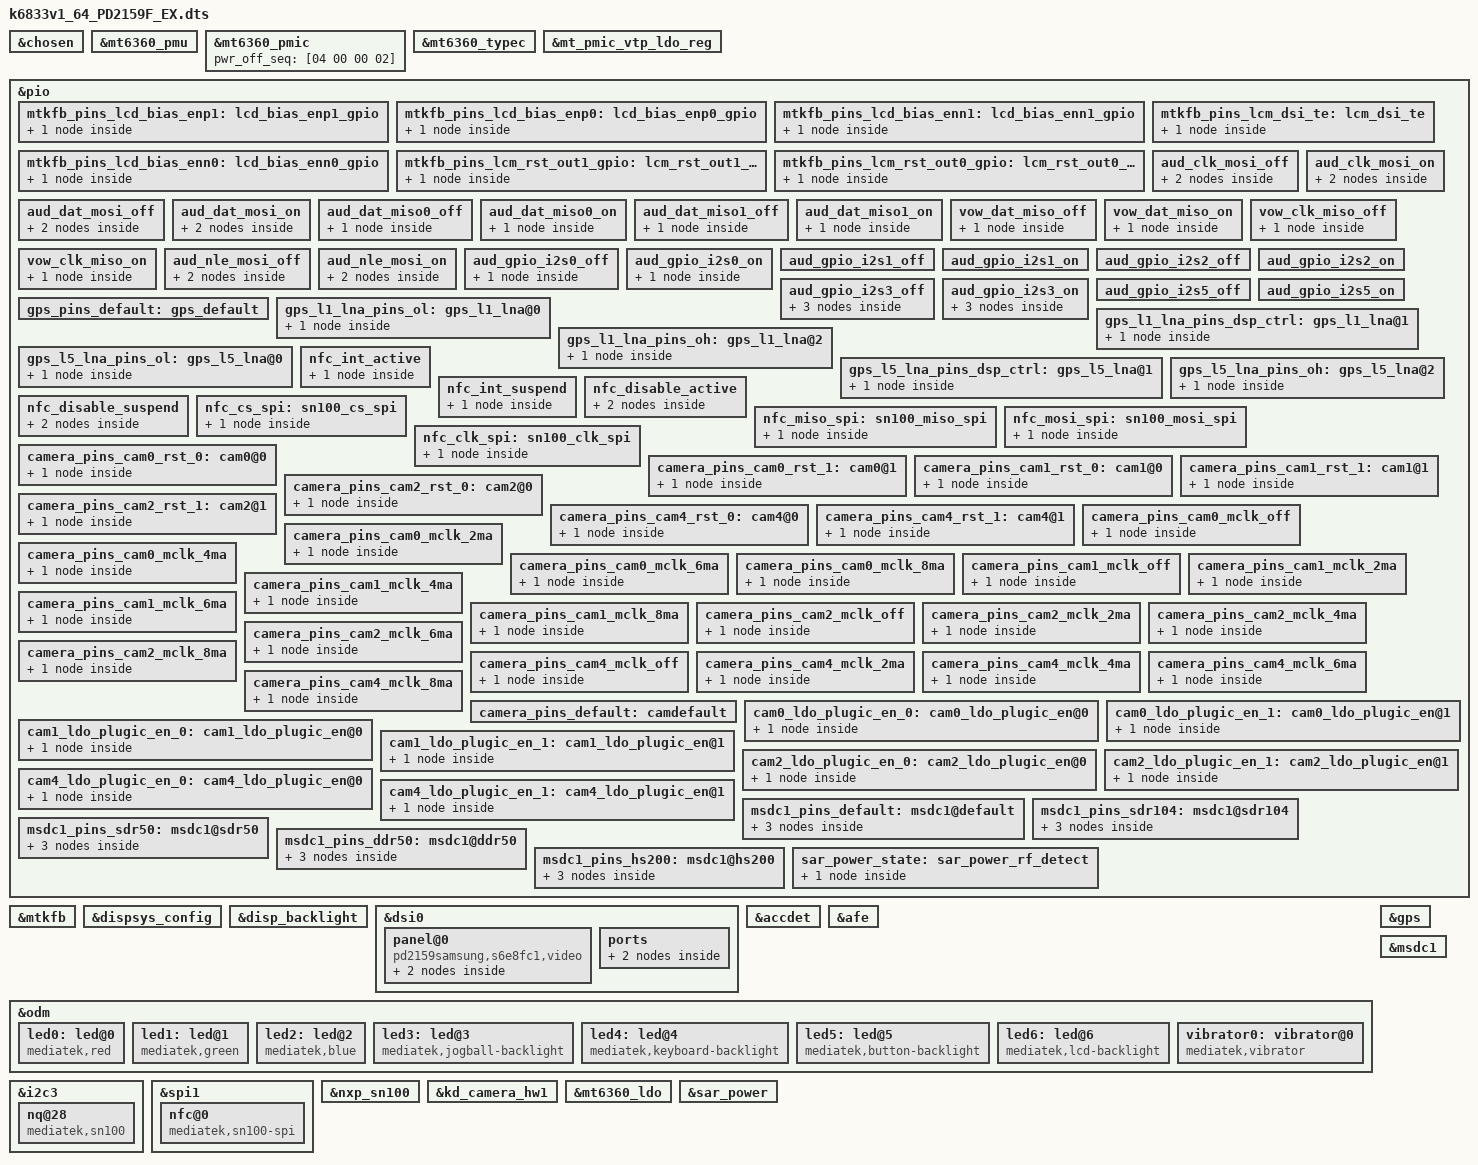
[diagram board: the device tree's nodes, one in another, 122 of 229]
/*
 * Mediatek's mt6833 SoC device tree source
 *
 * Copyright (C) 2016 MediaTek Inc.
 *
 * This program is free software; you can redistribute it and/or modify
 * it under the terms of the GNU General Public License version 2 as
 * published by the Free Software Foundation.
 *
 * This program is distributed in the hope that it will be useful,
 * but WITHOUT ANY WARRANTY; without even the implied warranty of
 * MERCHANTABILITY or FITNESS FOR A PARTICULAR PURPOSE.
 * See http://www.gnu.org/licenses/gpl-2.0.html for more details.
 */
/dts-v1/;
/plugin/;
#include <generated/autoconf.h>
#include <dt-bindings/interrupt-controller/irq.h>
#include <dt-bindings/interrupt-controller/arm-gic.h>
#ifndef CONFIG_FPGA_EARLY_PORTING
#include <dt-bindings/pinctrl/mt6833-pinfunc.h>
#endif

/* chosen */
&chosen {
	atag,videolfb-fb_base_l = <0x7e605000>;
	atag,videolfb-fb_base_h = <0x0>;
	atag,videolfb-islcmfound = <1>;
	atag,videolfb-islcm_inited = <0>;
	atag,videolfb-fps= <6000>;
	atag,videolfb-vramSize= <0x1be0000>;
	atag,videolfb-lcmname=
		"nt35595_fhd_dsi_cmd_truly_nt50358_drv";
	atag,videolfb-project-name= "pd2159";
	atag,vivo-dsi-panel-type = "oled";
	atag,exception-event-support;
	default-backlight-level = <573>;
//	bias-ic-use-i2c = <6>;
//	bl-ic-use-i2c = <6>;
};

&mt6360_pmu {
	mt6360,intr_gpio_num = <10>; /* direct defined GPIO num */
	mt6360,intr_gpio = <&pio 10 0x0>;
};

&mt6360_pmic {
	pwr_off_seq = [04 00 00 02];
};

&mt6360_typec {
	mt6360pd,intr_gpio_num = <9>; /* direct defined GPIO num */
	mt6360pd,intr_gpio = <&pio 9 0x0>;
};

/* add by sensor team for Psensor LED LDO2*/
&mt_pmic_vtp_ldo_reg {
	regulator-min-microvolt = <3000000>;
	regulator-max-microvolt = <3000000>;
	regulator-always-on;
};

#ifndef CONFIG_FPGA_EARLY_PORTING
&pio {
	mtkfb_pins_lcd_bias_enp1: lcd_bias_enp1_gpio {
		pins_cmd_dat {
			pinmux = <PINMUX_GPIO137__FUNC_GPIO137>;
			slew-rate = <1>;
			output-high;
		};
	};

	mtkfb_pins_lcd_bias_enp0: lcd_bias_enp0_gpio {
		pins_cmd_dat {
			pinmux = <PINMUX_GPIO137__FUNC_GPIO137>;
			slew-rate = <1>;
			output-low;
		};
	};

	mtkfb_pins_lcd_bias_enn1: lcd_bias_enn1_gpio {
		pins_cmd_dat {
			pinmux = <PINMUX_GPIO138__FUNC_GPIO138>;
			slew-rate = <1>;
			output-high;
		};
	};

	mtkfb_pins_lcd_bias_enn0: lcd_bias_enn0_gpio {
		pins_cmd_dat {
			pinmux = <PINMUX_GPIO138__FUNC_GPIO138>;
			slew-rate = <1>;
			output-low;
		};
	};

	mtkfb_pins_lcm_rst_out1_gpio: lcm_rst_out1_gpio {
		pins_cmd_dat {
			pinmux = <PINMUX_GPIO86__FUNC_GPIO86>;
			slew-rate = <1>;
			output-high;
		};
	};

	mtkfb_pins_lcm_rst_out0_gpio: lcm_rst_out0_gpio {
		pins_cmd_dat {
			pinmux = <PINMUX_GPIO86__FUNC_GPIO86>;
			slew-rate = <1>;
			output-low;
		};
	};
	mtkfb_pins_lcm_dsi_te: lcm_dsi_te {
		pins_cmd_dat {
			pinmux = <PINMUX_GPIO84__FUNC_DSI_TE>;
		};
	};
};

&mtkfb {
	pinctrl-names = "lcd_bias_enp1_gpio", "lcd_bias_enp0_gpio",
		"lcd_bias_enn1_gpio", "lcd_bias_enn0_gpio",
		"lcm_rst_out1_gpio", "lcm_rst_out0_gpio",
		"mode_te_te";
	pinctrl-0 = <&mtkfb_pins_lcd_bias_enp1>;
	pinctrl-1 = <&mtkfb_pins_lcd_bias_enp0>;
	pinctrl-2 = <&mtkfb_pins_lcd_bias_enn1>;
	pinctrl-3 = <&mtkfb_pins_lcd_bias_enn0>;
	pinctrl-4 = <&mtkfb_pins_lcm_rst_out1_gpio>;
	pinctrl-5 = <&mtkfb_pins_lcm_rst_out0_gpio>;
	pinctrl-6 = <&mtkfb_pins_lcm_dsi_te>;
	status = "okay";
};
&dispsys_config {
	pinctrl-names =
		"lcm_rst_out1_gpio", "lcm_rst_out0_gpio",
		"mode_te_te";
	pinctrl-0 = <&mtkfb_pins_lcm_rst_out1_gpio>;
	pinctrl-1 = <&mtkfb_pins_lcm_rst_out0_gpio>;
	pinctrl-2 = <&mtkfb_pins_lcm_dsi_te>;
	status = "okay";
		helper-name = "MTK_DRM_OPT_STAGE",
			"MTK_DRM_OPT_USE_CMDQ",
			"MTK_DRM_OPT_USE_M4U",
			"MTK_DRM_OPT_SODI_SUPPORT",
			"MTK_DRM_OPT_IDLE_MGR",
			"MTK_DRM_OPT_IDLEMGR_SWTCH_DECOUPLE",
			"MTK_DRM_OPT_IDLEMGR_BY_REPAINT",
			"MTK_DRM_OPT_IDLEMGR_ENTER_ULPS",
			"MTK_DRM_OPT_IDLEMGR_KEEP_LP11",
			"MTK_DRM_OPT_DYNAMIC_RDMA_GOLDEN_SETTING",
			"MTK_DRM_OPT_IDLEMGR_DISABLE_ROUTINE_IRQ",
			"MTK_DRM_OPT_MET_LOG",
			"MTK_DRM_OPT_USE_PQ",
			"MTK_DRM_OPT_ESD_CHECK_RECOVERY",
			"MTK_DRM_OPT_ESD_CHECK_SWITCH",
			"MTK_DRM_OPT_PRESENT_FENCE",
			"MTK_DRM_OPT_RDMA_UNDERFLOW_AEE",
			"MTK_DRM_OPT_DSI_UNDERRUN_AEE",
			"MTK_DRM_OPT_HRT",
			"MTK_DRM_OPT_HRT_MODE",
			"MTK_DRM_OPT_DELAYED_TRIGGER",
			"MTK_DRM_OPT_OVL_EXT_LAYER",
			"MTK_DRM_OPT_AOD",
			"MTK_DRM_OPT_RPO",
			"MTK_DRM_OPT_DUAL_PIPE",
			"MTK_DRM_OPT_DC_BY_HRT",
			"MTK_DRM_OPT_OVL_WCG",
			"MTK_DRM_OPT_OVL_SBCH",
			"MTK_DRM_OPT_COMMIT_NO_WAIT_VBLANK",
			"MTK_DRM_OPT_MET",
			"MTK_DRM_OPT_REG_PARSER_RAW_DUMP",
			"MTK_DRM_OPT_VP_PQ",
			"MTK_DRM_OPT_GAME_PQ",
			"MTK_DRM_OPT_MMPATH",
			"MTK_DRM_OPT_HBM",
			"MTK_DRM_OPT_VDS_PATH_SWITCH",
			"MTK_DRM_OPT_LAYER_REC",
			"MTK_DRM_OPT_CLEAR_LAYER";

		helper-value = <0>, /*MTK_DRM_OPT_STAGE*/
			<1>, /*MTK_DRM_OPT_USE_CMDQ*/
			<1>, /*MTK_DRM_OPT_USE_M4U*/
			<0>, /*MTK_DRM_OPT_SODI_SUPPORT*/
			<1>, /*MTK_DRM_OPT_IDLE_MGR*/
			<0>, /*MTK_DRM_OPT_IDLEMGR_SWTCH_DECOUPLE*/
			<1>, /*MTK_DRM_OPT_IDLEMGR_BY_REPAINT*/
			<0>, /*MTK_DRM_OPT_IDLEMGR_ENTER_ULPS*/
			<0>, /*MTK_DRM_OPT_IDLEMGR_KEEP_LP11*/
			<0>, /*MTK_DRM_OPT_DYNAMIC_RDMA_GOLDEN_SETTING*/
			<1>, /*MTK_DRM_OPT_IDLEMGR_DISABLE_ROUTINE_IRQ*/
			<0>, /*MTK_DRM_OPT_MET_LOG*/
			<1>, /*MTK_DRM_OPT_USE_PQ*/
			<1>, /*MTK_DRM_OPT_ESD_CHECK_RECOVERY*/
			<1>, /*MTK_DRM_OPT_ESD_CHECK_SWITCH*/
			<1>, /*MTK_DRM_OPT_PRESENT_FENCE*/
			<0>, /*MTK_DRM_OPT_RDMA_UNDERFLOW_AEE*/
			<1>, /*MTK_DRM_OPT_DSI_UNDERRUN_AEE*/
			<1>, /*MTK_DRM_OPT_HRT*/
			<1>, /*MTK_DRM_OPT_HRT_MODE*/
			<0>, /*MTK_DRM_OPT_DELAYED_TRIGGER*/
			<1>, /*MTK_DRM_OPT_OVL_EXT_LAYER*/
			<1>, /*MTK_DRM_OPT_AOD*/
			<1>, /*MTK_DRM_OPT_RPO*/
			<0>, /*MTK_DRM_OPT_DUAL_PIPE*/
			<0>, /*MTK_DRM_OPT_DC_BY_HRT*/
			<0>, /*MTK_DRM_OPT_OVL_WCG*/
			<0>, /*MTK_DRM_OPT_OVL_SBCH*/
			<1>, /*MTK_DRM_OPT_COMMIT_NO_WAIT_VBLANK*/
			<0>, /*MTK_DRM_OPT_MET*/
			<0>, /*MTK_DRM_OPT_REG_PARSER_RAW_DUMP*/
			<0>, /*MTK_DRM_OPT_VP_PQ*/
			<0>, /*MTK_DRM_OPT_GAME_PQ*/
			<0>, /*MTK_DRM_OPT_MMPATH*/
			<1>, /*MTK_DRM_OPT_HBM*/
			<1>, /*MTK_DRM_OPT_VDS_PATH_SWITCH*/
			<0>, /*MTK_DRM_OPT_LAYER_REC*/
			<1>; /*MTK_DRM_OPT_CLEAR_LAYER*/
};
&disp_backlight {
	max-brightness = <2047>;
	led-bits = <11>;
	default-state = "on";
};
&dsi0 {
	status = "okay";
	#address-cells = <1>;
	#size-cells = <0>;
	panel@0 {
		compatible = "pd2159samsung,s6e8fc1,video";
		reg = <0>;
		lcm_vci-supply = <&mt_pmic_vfp_ldo_reg>;
		reset-gpios = <&pio 86 0>;
		elvdd_ctrl-gpio = <&pio 137 0>;
		pinctrl-names = "default";
		port {
			panel_in1: endpoint {
				remote-endpoint = <&dsi_out>;
			};
		};
	};
	ports {
		port {
			dsi_out: endpoint {
				remote-endpoint = <&panel_in1>;
			};
		};
	};
};
#endif

/* accdet start */
&accdet {
	/* accdet micbias voltage: 0x09:2.85v 0x08:2.8v 0x07,
	 * 2.7v;0x05,2.5v;0x02,1.9v
	 */
	accdet-mic-vol = <7>;
	/* accdet pwm_width, pwm_thresh, fall_delay, rise_delay
	 * debounce0, debounce1, debounce3, debounce4
	 * eint pwm_width, eint pwm_thresh
	 * eint deb(debounce0, debounce1, debounce2, debounce3), inv_debounce
	 */
	headset-mode-setting = <0x500 0x500 1 0x1f0
				0x800 0x800 0x20 0x44
				0x4 0x1
				0x5 0x3 0x3 0x5 0xe>;
	accdet-plugout-debounce = <16>;
	/*1:ACC mode, 2:low cost without in bias, 6:low cost with in bias*/
	accdet-mic-mode = <2>;
	/*0--MD_MAX--UP_MAX--DW_MAX*/
	headset-three-key-threshold = <0 90 210 430>;
	headset-three-key-threshold-CDD = <0 121 192 600>;
	/*0--MD_MAX--VOICE_MAX--UP_MAX--DW_MAX*/
	headset-four-key-threshold = <0 56 98 206 435>;

	/* select VTH to 2v and 500k, use internal resitance */
	eint_use_ext_res = <0>;
	status = "okay";
};

/* accdet end */

/* audio config start */
&afe {
	pinctrl-names = "aud_clk_mosi_off",
				"aud_clk_mosi_on",
				"aud_dat_mosi_off",
				"aud_dat_mosi_on",
				"aud_dat_miso0_off",
				"aud_dat_miso0_on",
				"aud_dat_miso1_off",
				"aud_dat_miso1_on",
				"vow_dat_miso_off",
				"vow_dat_miso_on",
				"vow_clk_miso_off",
				"vow_clk_miso_on",
				"aud_nle_mosi_off",
				"aud_nle_mosi_on",
				"aud_gpio_i2s0_off",
				"aud_gpio_i2s0_on",
				"aud_gpio_i2s1_off",
				"aud_gpio_i2s1_on",
				"aud_gpio_i2s2_off",
				"aud_gpio_i2s2_on",
				"aud_gpio_i2s3_off",
				"aud_gpio_i2s3_on",
				"aud_gpio_i2s5_off",
				"aud_gpio_i2s5_on";

		pinctrl-0 = <&aud_clk_mosi_off>;
		pinctrl-1 = <&aud_clk_mosi_on>;
		pinctrl-2 = <&aud_dat_mosi_off>;
		pinctrl-3 = <&aud_dat_mosi_on>;
		pinctrl-4 = <&aud_dat_miso0_off>;
		pinctrl-5 = <&aud_dat_miso0_on>;
		pinctrl-6 = <&aud_dat_miso1_off>;
		pinctrl-7 = <&aud_dat_miso1_on>;
		pinctrl-8 = <&vow_dat_miso_off>;
		pinctrl-9 = <&vow_dat_miso_on>;
		pinctrl-10 = <&vow_clk_miso_off>;
		pinctrl-11 = <&vow_clk_miso_on>;
		pinctrl-12 = <&aud_nle_mosi_off>;
		pinctrl-13 = <&aud_nle_mosi_on>;
		pinctrl-14 = <&aud_gpio_i2s0_off>;
		pinctrl-15 = <&aud_gpio_i2s0_on>;
		pinctrl-16 = <&aud_gpio_i2s1_off>;
		pinctrl-17 = <&aud_gpio_i2s1_on>;
		pinctrl-18 = <&aud_gpio_i2s2_off>;
		pinctrl-19 = <&aud_gpio_i2s2_on>;
		pinctrl-20 = <&aud_gpio_i2s3_off>;
		pinctrl-21 = <&aud_gpio_i2s3_on>;
		pinctrl-22 = <&aud_gpio_i2s5_off>;
		pinctrl-23 = <&aud_gpio_i2s5_on>;
};

&pio {
	aud_clk_mosi_off: aud_clk_mosi_off {
		pins_cmd0_dat {
			pinmux = <PINMUX_GPIO152__FUNC_GPIO152>;
			input-enable;
			drive-strength = <2>;
			bias-pull-down;
		};
		pins_cmd1_dat {
			pinmux = <PINMUX_GPIO153__FUNC_GPIO153>;
			input-enable;
			drive-strength = <2>;
			bias-pull-down;
		};
	};
	aud_clk_mosi_on: aud_clk_mosi_on {
		pins_cmd0_dat {
			pinmux = <PINMUX_GPIO152__FUNC_AUD_CLK_MOSI>;
			input-schmitt-enable;
			drive-strength = <2>;
			bias-disable;
		};
		pins_cmd1_dat {
			pinmux = <PINMUX_GPIO153__FUNC_AUD_SYNC_MOSI>;
			input-schmitt-enable;
			drive-strength = <2>;
			bias-disable;
		};
	};
	aud_dat_mosi_off: aud_dat_mosi_off {
		pins_cmd1_dat {
			pinmux = <PINMUX_GPIO154__FUNC_GPIO154>;
			input-enable;
			bias-pull-down;
		};
		pins_cmd2_dat {
			pinmux = <PINMUX_GPIO155__FUNC_GPIO155>;
			input-enable;
			bias-pull-down;
		};
	};
	aud_dat_mosi_on: aud_dat_mosi_on {
		pins_cmd1_dat {
			pinmux = <PINMUX_GPIO154__FUNC_AUD_DAT_MOSI0>;
			input-schmitt-enable;
			bias-disable;
		};
		pins_cmd2_dat {
			pinmux = <PINMUX_GPIO155__FUNC_AUD_DAT_MOSI1>;
			input-schmitt-enable;
			bias-disable;
		};
	};
	aud_dat_miso0_off: aud_dat_miso0_off {
		pins_cmd1_dat {
			pinmux = <PINMUX_GPIO159__FUNC_GPIO159>;
			input-enable;
			bias-pull-down;
		};
	};
	aud_dat_miso0_on: aud_dat_miso0_on {
		pins_cmd1_dat {
			pinmux = <PINMUX_GPIO159__FUNC_AUD_DAT_MISO0>;
			input-schmitt-enable;
			bias-disable;
		};
	};
	aud_dat_miso1_off: aud_dat_miso1_off {
		pins_cmd1_dat {
			pinmux = <PINMUX_GPIO160__FUNC_GPIO160>;
			input-enable;
			bias-pull-down;
		};
	};
	aud_dat_miso1_on: aud_dat_miso1_on {
		pins_cmd1_dat {
			pinmux = <PINMUX_GPIO160__FUNC_AUD_DAT_MISO1>;
			input-schmitt-enable;
			bias-disable;
		};
	};

	vow_dat_miso_off: vow_dat_miso_off {
		pins_cmd1_dat {
			pinmux = <PINMUX_GPIO159__FUNC_GPIO159>;
			input-enable;
			bias-pull-down;
		};
	};
	vow_dat_miso_on: vow_dat_miso_on {
		pins_cmd1_dat {
			pinmux = <PINMUX_GPIO159__FUNC_VOW_DAT_MISO>;
			input-schmitt-enable;
			bias-disable;
		};
	};
	vow_clk_miso_off: vow_clk_miso_off {
		pins_cmd3_dat {
			pinmux = <PINMUX_GPIO160__FUNC_GPIO160>;
			input-enable;
			bias-pull-down;
		};
	};
	vow_clk_miso_on: vow_clk_miso_on {
		pins_cmd1_dat {
			pinmux = <PINMUX_GPIO160__FUNC_VOW_CLK_MISO>;
			input-schmitt-enable;
			bias-disable;
		};
	};
	aud_nle_mosi_off: aud_nle_mosi_off {
		pins_cmd1_dat {
			pinmux = <PINMUX_GPIO158__FUNC_GPIO158>;
			input-enable;
			bias-pull-down;
		};
		pins_cmd2_dat {
			pinmux = <PINMUX_GPIO157__FUNC_GPIO157>;
			input-enable;
			bias-pull-down;
		};
	};
	aud_nle_mosi_on: aud_nle_mosi_on {
		pins_cmd1_dat {
			pinmux = <PINMUX_GPIO158__FUNC_AUD_NLE_MOSI1>;
			input-schmitt-enable;
			bias-disable;
		};
		pins_cmd2_dat {
			pinmux = <PINMUX_GPIO157__FUNC_AUD_NLE_MOSI0>;
			input-schmitt-enable;
			bias-disable;
		};
	};
	aud_gpio_i2s0_off: aud_gpio_i2s0_off {
		pins_cmd1_dat {
			pinmux = <PINMUX_GPIO42__FUNC_GPIO42>;
			input-enable;
			bias-pull-down;
		};
	};
	aud_gpio_i2s0_on: aud_gpio_i2s0_on {
		pins_cmd1_dat {
			pinmux = <PINMUX_GPIO42__FUNC_I2S0_DI>;
			input-schmitt-enable;
			bias-disable;
		};
	};
	aud_gpio_i2s1_off: aud_gpio_i2s1_off {
	};
	aud_gpio_i2s1_on: aud_gpio_i2s1_on {
	};
	aud_gpio_i2s2_off: aud_gpio_i2s2_off {
	};
	aud_gpio_i2s2_on: aud_gpio_i2s2_on {
	};
	aud_gpio_i2s3_off: aud_gpio_i2s3_off {
		pins_cmd1_dat {
			pinmux = <PINMUX_GPIO40__FUNC_GPIO40>;
			input-enable;
			bias-pull-down;
		};
		pins_cmd2_dat {
			pinmux = <PINMUX_GPIO41__FUNC_GPIO41>;
			input-enable;
			bias-pull-down;
		};
		pins_cmd3_dat {
			pinmux = <PINMUX_GPIO43__FUNC_GPIO43>;
			input-enable;
			bias-pull-down;
		};
	};
	aud_gpio_i2s3_on: aud_gpio_i2s3_on {
		pins_cmd1_dat {
			pinmux = <PINMUX_GPIO40__FUNC_I2S3_BCK>;
			input-schmitt-enable;
			bias-disable;
		};
		pins_cmd2_dat {
			pinmux = <PINMUX_GPIO41__FUNC_I2S3_LRCK>;
			input-schmitt-enable;
			bias-disable;
		};
		pins_cmd3_dat {
			pinmux = <PINMUX_GPIO43__FUNC_I2S3_DO>;
			input-schmitt-enable;
			bias-disable;
		};
	};
	aud_gpio_i2s5_off: aud_gpio_i2s5_off {
	};
	aud_gpio_i2s5_on: aud_gpio_i2s5_on {
	};
};
/* audio config end */

&odm {
	led0:led@0 {
		compatible = "mediatek,red";
		led_mode = <0>;
		data = <1>;
		pwm_config = <0 0 0 0 0>;
	};
	led1:led@1 {
		compatible = "mediatek,green";
		led_mode = <0>;
		data = <1>;
		pwm_config = <0 0 0 0 0>;
	};
	led2:led@2 {
		compatible = "mediatek,blue";
		led_mode = <0>;
		data = <1>;
		pwm_config = <0 0 0 0 0>;
	};
	led3:led@3 {
		compatible = "mediatek,jogball-backlight";
		led_mode = <0>;
		data = <1>;
		pwm_config = <0 0 0 0 0>;
	};
	led4:led@4 {
		compatible = "mediatek,keyboard-backlight";
		led_mode = <0>;
		data = <1>;
		pwm_config = <0 0 0 0 0>;
	};
	led5:led@5 {
		compatible = "mediatek,button-backlight";
		led_mode = <0>;
		data = <1>;
		pwm_config = <0 0 0 0 0>;
	};
	led6:led@6 {
		compatible = "mediatek,lcd-backlight";
		led_mode = <4>; /*5:cpu pwm 4:lcm pwm*/
		data = <1>;
		pwm_config = <0 1 0 0 0>;
	};
	vibrator0:vibrator@0 {
		compatible = "mediatek,vibrator";
		vib_timer = <25>;
		vib_limit = <9>;
		vib_vol= <11>;
	};
};
/* GPS GPIO standardization start */
&pio {
	gps_pins_default: gps_default {
	};

	gps_l1_lna_pins_ol: gps_l1_lna@0 {
		pins_cmd_dat {
			pinmux = <PINMUX_GPIO87__FUNC_GPIO87>;
			output-low;
		};
	};
	gps_l1_lna_pins_dsp_ctrl: gps_l1_lna@1 {
		pins_cmd_dat {
			pinmux = <PINMUX_GPIO87__FUNC_GPS_L1_ELNA_EN>;
		};
	};
	gps_l1_lna_pins_oh: gps_l1_lna@2 {
		pins_cmd_dat {
			pinmux = <PINMUX_GPIO87__FUNC_GPIO87>;
			output-high;
		};
	};

	gps_l5_lna_pins_ol: gps_l5_lna@0 {
		pins_cmd_dat {
			pinmux = <PINMUX_GPIO91__FUNC_GPIO91>;
			output-low;
		};
	};
	gps_l5_lna_pins_dsp_ctrl: gps_l5_lna@1 {
		pins_cmd_dat {
			pinmux = <PINMUX_GPIO91__FUNC_GPS_L5_ELNA_EN>;
		};
	};
	gps_l5_lna_pins_oh: gps_l5_lna@2 {
		pins_cmd_dat {
			pinmux = <PINMUX_GPIO91__FUNC_GPIO91>;
			output-high;
		};
	};
};

&gps {
	pinctrl-names = "default",
		"gps_l1_lna_disable",
		"gps_l1_lna_dsp_ctrl",
		"gps_l1_lna_enable",
		"gps_l5_lna_disable",
		"gps_l5_lna_dsp_ctrl",
		"gps_l5_lna_enable";
	pinctrl-0 = <&gps_pins_default>;
	pinctrl-1 = <&gps_l1_lna_pins_ol>;
	pinctrl-2 = <&gps_l1_lna_pins_dsp_ctrl>;
	pinctrl-3 = <&gps_l1_lna_pins_oh>;
	pinctrl-4 = <&gps_l5_lna_pins_ol>;
	pinctrl-5 = <&gps_l5_lna_pins_dsp_ctrl>;
	pinctrl-6 = <&gps_l5_lna_pins_oh>;
	status = "okay";
};
/* GPS GPIO standardization end */

/* NFC GPIO standardization begin*/
&pio {
	nfc_int_active: nfc_int_active {
		pins_cmd0_dat {
			pinmux = <PINMUX_GPIO5__FUNC_GPIO5>;
			bias-pull-up;
		};
	};
	nfc_int_suspend: nfc_int_suspend {
		pins_cmd0_dat {
			pinmux = <PINMUX_GPIO5__FUNC_GPIO5>;
			bias-pull-up;
		};
	};
	nfc_disable_active: nfc_disable_active {
		pins_cmd0_dat {
			pinmux = <PINMUX_GPIO67__FUNC_GPIO67>;
			bias-pull-up;
		};
		pins_cmd1_dat {
			pinmux = <PINMUX_GPIO176__FUNC_GPIO176>;
			bias-pull-up;
		};
	};
	nfc_disable_suspend: nfc_disable_suspend {
		pins_cmd0_dat {
			pinmux = <PINMUX_GPIO67__FUNC_GPIO67>;
			bias-disable;
		};
		pins_cmd1_dat {
			pinmux = <PINMUX_GPIO176__FUNC_GPIO176>;
			bias-disable;
		};
	};

};
&i2c3 {
	status = "okay";
	#address-cells = <1>;
	#size-cells = <0>;
	clock-frequency = <400000>;
	mediatek,use-open-drain;
	nq@28 {
		compatible = "mediatek,sn100";
		reg = <0x28>;
		vivo,nfc_support = <1>;
		vivo,boardversion_shift = <6>;
		vivo,boardversion_mask = <1>;
		vivo,boardversion_num = <0>;
		vivo,boardversions = "0";
		mediatek,nq-irq = <&pio 5 0x00>;
		mediatek,nq-ven = <&pio 67 0x00>;
		mediatek,nq-firm = <&pio 176 0x00>;
		//mediatek,nq-clkreq = <&pio 81 0x00>;
		interrupt-parent = <&pio>;
		interrupts = <5 0>;
		interrupt-names = "nfc_irq";
		pinctrl-names = "nfc_active", "nfc_suspend";
		pinctrl-0 = <&nfc_int_active &nfc_disable_active>;
		pinctrl-1 = <&nfc_int_suspend &nfc_disable_suspend>;
	};
};
/* NFC GPIO standardization end*/
/* NFC SPI standardization begin*/
&spi1 {
	#address-cells = <1>;
	#size-cells = <0>;
	nfc@0 {
		compatible = "mediatek,sn100-spi";
		reg = <0>;
		spi-max-frequency = <10000000>;
		status = "okay";
	};
};

&nxp_sn100 {
    status = "okay";
	pinctrl-names = "miso_spi","mosi_spi","cs_spi","clk_spi";
	pinctrl-0 = <&nfc_miso_spi>;
	pinctrl-1 = <&nfc_mosi_spi>;
	pinctrl-2 = <&nfc_cs_spi>;
	pinctrl-3 = <&nfc_clk_spi>;

};

&pio {
	nfc_miso_spi: sn100_miso_spi {
		pins_cmd_dat {
			pinmux = <PINMUX_GPIO30__FUNC_SPI1_MI>;
			drive-strength = <4>;
		};
	};
	nfc_mosi_spi: sn100_mosi_spi {
		pins_cmd_dat {
			pinmux = <PINMUX_GPIO29__FUNC_SPI1_MO>;
			drive-strength = <2>;
		};
	};
	nfc_cs_spi: sn100_cs_spi {
		pins_cmd_dat {
			pinmux = <PINMUX_GPIO28__FUNC_SPI1_CSB>;
			drive-strength = <4>;
			//bias-pull-up;
		};
	};
	nfc_clk_spi: sn100_clk_spi {
		pins_cmd_dat {
			pinmux = <PINMUX_GPIO27__FUNC_SPI1_CLK>;
			drive-strength = <1>;
		};
	};
};
/* NFC SPI standardization end*/

/* CAMERA GPIO standardization */
&pio {
	camera_pins_cam0_rst_0: cam0@0 {
		pins_cmd_dat {
			pinmux = <PINMUX_GPIO54__FUNC_GPIO54>;
			slew-rate = <1>;
			output-low;
		};
	};
	camera_pins_cam0_rst_1: cam0@1 {
		pins_cmd_dat {
			pinmux = <PINMUX_GPIO54__FUNC_GPIO54>;
			slew-rate = <1>;
			output-high;
		};
	};
	camera_pins_cam1_rst_0: cam1@0 {
		pins_cmd_dat {
			pinmux = <PINMUX_GPIO60__FUNC_GPIO60>;
			slew-rate = <1>;
			output-low;
		};
	};
	camera_pins_cam1_rst_1: cam1@1 {
		pins_cmd_dat {
			pinmux = <PINMUX_GPIO60__FUNC_GPIO60>;
			slew-rate = <1>;
			output-high;
		};
	};
	camera_pins_cam2_rst_0: cam2@0 {
		pins_cmd_dat {
			pinmux = <PINMUX_GPIO58__FUNC_GPIO58>;
			slew-rate = <1>;
			output-low;
		};
	};
	camera_pins_cam2_rst_1: cam2@1 {
		pins_cmd_dat {
			pinmux = <PINMUX_GPIO58__FUNC_GPIO58>;
			slew-rate = <1>;
			output-high;
		};
	};
	camera_pins_cam4_rst_0: cam4@0 {
		pins_cmd_dat {
			pinmux = <PINMUX_GPIO56__FUNC_GPIO56>;
			slew-rate = <1>;
			output-low;
		};
	};
	camera_pins_cam4_rst_1: cam4@1 {
		pins_cmd_dat {
			pinmux = <PINMUX_GPIO56__FUNC_GPIO56>;
			slew-rate = <1>;
			output-high;
		};
	};
	camera_pins_cam0_mclk_off: camera_pins_cam0_mclk_off {
		pins_cmd_dat {
			pinmux = <PINMUX_GPIO49__FUNC_GPIO49>;
			drive-strength = <1>;
		};
	};
	camera_pins_cam0_mclk_2ma: camera_pins_cam0_mclk_2ma {
		pins_cmd_dat {
			pinmux = <PINMUX_GPIO49__FUNC_CMMCLK0>;
			drive-strength = <0>;
		};
	};
	camera_pins_cam0_mclk_4ma: camera_pins_cam0_mclk_4ma {
		pins_cmd_dat {
			pinmux = <PINMUX_GPIO49__FUNC_CMMCLK0>;
			drive-strength = <1>;
		};
	};
	camera_pins_cam0_mclk_6ma: camera_pins_cam0_mclk_6ma {
		pins_cmd_dat {
			pinmux = <PINMUX_GPIO49__FUNC_CMMCLK0>;
			drive-strength = <2>;
		};
	};
	camera_pins_cam0_mclk_8ma: camera_pins_cam0_mclk_8ma {
		pins_cmd_dat {
			pinmux = <PINMUX_GPIO49__FUNC_CMMCLK0>;
			drive-strength = <3>;
		};
	};

	camera_pins_cam1_mclk_off: camera_pins_cam1_mclk_off {
		pins_cmd_dat {
			pinmux = <PINMUX_GPIO52__FUNC_GPIO52>;
			drive-strength = <1>;
		};
	};
	camera_pins_cam1_mclk_2ma: camera_pins_cam1_mclk_2ma {
		pins_cmd_dat {
			pinmux = <PINMUX_GPIO52__FUNC_CMMCLK3>;
			drive-strength = <0>;
		};
	};
	camera_pins_cam1_mclk_4ma: camera_pins_cam1_mclk_4ma {
		pins_cmd_dat {
			pinmux = <PINMUX_GPIO52__FUNC_CMMCLK3>;
			drive-strength = <1>;
		};
	};
	camera_pins_cam1_mclk_6ma: camera_pins_cam1_mclk_6ma {
		pins_cmd_dat {
			pinmux = <PINMUX_GPIO52__FUNC_CMMCLK3>;
			drive-strength = <2>;
		};
	};
	camera_pins_cam1_mclk_8ma: camera_pins_cam1_mclk_8ma {
		pins_cmd_dat {
			pinmux = <PINMUX_GPIO52__FUNC_CMMCLK3>;
			drive-strength = <3>;
		};
	};
	camera_pins_cam2_mclk_off: camera_pins_cam2_mclk_off {
		pins_cmd_dat {
			pinmux = <PINMUX_GPIO51__FUNC_GPIO51>;
			drive-strength = <1>;
		};
	};
	camera_pins_cam2_mclk_2ma: camera_pins_cam2_mclk_2ma {
		pins_cmd_dat {
			pinmux = <PINMUX_GPIO51__FUNC_CMMCLK2>;
			drive-strength = <0>;
		};
	};
	camera_pins_cam2_mclk_4ma: camera_pins_cam2_mclk_4ma {
		pins_cmd_dat {
			pinmux = <PINMUX_GPIO51__FUNC_CMMCLK2>;
			drive-strength = <1>;
		};
	};
	camera_pins_cam2_mclk_6ma: camera_pins_cam2_mclk_6ma {
		pins_cmd_dat {
			pinmux = <PINMUX_GPIO51__FUNC_CMMCLK2>;
			drive-strength = <2>;
		};
	};
	camera_pins_cam2_mclk_8ma: camera_pins_cam2_mclk_8ma {
		pins_cmd_dat {
			pinmux = <PINMUX_GPIO51__FUNC_CMMCLK2>;
			drive-strength = <3>;
		};
	};

	camera_pins_cam4_mclk_off: camera_pins_cam4_mclk_off {
		pins_cmd_dat {
			pinmux = <PINMUX_GPIO50__FUNC_GPIO50>;
			drive-strength = <1>;
		};
	};
	camera_pins_cam4_mclk_2ma: camera_pins_cam4_mclk_2ma {
		pins_cmd_dat {
			pinmux = <PINMUX_GPIO50__FUNC_CMMCLK1>;
			drive-strength = <0>;
		};
	};
	camera_pins_cam4_mclk_4ma: camera_pins_cam4_mclk_4ma {
		pins_cmd_dat {
			pinmux = <PINMUX_GPIO50__FUNC_CMMCLK1>;
			drive-strength = <1>;
		};
	};
	camera_pins_cam4_mclk_6ma: camera_pins_cam4_mclk_6ma {
		pins_cmd_dat {
			pinmux = <PINMUX_GPIO50__FUNC_CMMCLK1>;
			drive-strength = <2>;
		};
	};
	camera_pins_cam4_mclk_8ma: camera_pins_cam4_mclk_8ma {
		pins_cmd_dat {
			pinmux = <PINMUX_GPIO50__FUNC_CMMCLK1>;
			drive-strength = <3>;
		};
	};
	camera_pins_default: camdefault {
	};
	cam0_ldo_plugic_en_0: cam0_ldo_plugic_en@0 {
		pins_cmd_dat {
			pinmux = <PINMUX_GPIO44__FUNC_GPIO44>;
			slew-rate = <1>;
			output-low;
		};
	};
	cam0_ldo_plugic_en_1: cam0_ldo_plugic_en@1 {
		pins_cmd_dat {
			pinmux = <PINMUX_GPIO44__FUNC_GPIO44>;
			slew-rate = <1>;
			output-high;
		};
	};
	cam1_ldo_plugic_en_0: cam1_ldo_plugic_en@0 {
		pins_cmd_dat {
			pinmux = <PINMUX_GPIO44__FUNC_GPIO44>;
			slew-rate = <1>;
			output-low;
		};
	};
	cam1_ldo_plugic_en_1: cam1_ldo_plugic_en@1 {
		pins_cmd_dat {
			pinmux = <PINMUX_GPIO44__FUNC_GPIO44>;
			slew-rate = <1>;
			output-high;
		};
	};
	cam2_ldo_plugic_en_0: cam2_ldo_plugic_en@0 {
		pins_cmd_dat {
			pinmux = <PINMUX_GPIO44__FUNC_GPIO44>;
			slew-rate = <1>;
			output-low;
		};
	};
	cam2_ldo_plugic_en_1: cam2_ldo_plugic_en@1 {
		pins_cmd_dat {
			pinmux = <PINMUX_GPIO44__FUNC_GPIO44>;
			slew-rate = <1>;
			output-high;
		};
	};
	cam4_ldo_plugic_en_0: cam4_ldo_plugic_en@0 {
		pins_cmd_dat {
			pinmux = <PINMUX_GPIO44__FUNC_GPIO44>;
			slew-rate = <1>;
			output-low;
		};
	};
	cam4_ldo_plugic_en_1: cam4_ldo_plugic_en@1 {
		pins_cmd_dat {
			pinmux = <PINMUX_GPIO44__FUNC_GPIO44>;
			slew-rate = <1>;
			output-high;
		};
	};
};
&kd_camera_hw1 {
	pinctrl-names = "default",
			"cam0_rst0", "cam0_rst1",
			"cam1_rst0", "cam1_rst1",
			"cam2_rst0", "cam2_rst1",
			"cam4_rst0", "cam4_rst1",
            "cam0_mclk_off",
			"cam0_mclk_2mA", "cam0_mclk_4mA",
			"cam0_mclk_6mA", "cam0_mclk_8mA",
			"cam1_mclk_off",
			"cam1_mclk_2mA", "cam1_mclk_4mA",
			"cam1_mclk_6mA", "cam1_mclk_8mA",
			"cam2_mclk_off",
			"cam2_mclk_2mA", "cam2_mclk_4mA",
			"cam2_mclk_6mA", "cam2_mclk_8mA",
			"cam4_mclk_off",
			"cam4_mclk_2mA", "cam4_mclk_4mA",
			"cam4_mclk_6mA", "cam4_mclk_8mA",
			"cam0_ldo_plugic_en_0", "cam0_ldo_plugic_en_1",
			"cam1_ldo_plugic_en_0", "cam1_ldo_plugic_en_1",
			"cam2_ldo_plugic_en_0", "cam2_ldo_plugic_en_1",
			"cam4_ldo_plugic_en_0", "cam4_ldo_plugic_en_1";
	pinctrl-0 = <&camera_pins_default>;
	pinctrl-1 = <&camera_pins_cam0_rst_0>;
	pinctrl-2 = <&camera_pins_cam0_rst_1>;
	pinctrl-3 = <&camera_pins_cam1_rst_0>;
	pinctrl-4 = <&camera_pins_cam1_rst_1>;
	pinctrl-5 = <&camera_pins_cam2_rst_0>;
	pinctrl-6 = <&camera_pins_cam2_rst_1>;
	pinctrl-7 = <&camera_pins_cam4_rst_0>;
	pinctrl-8 = <&camera_pins_cam4_rst_1>;
	pinctrl-9 = <&camera_pins_cam0_mclk_off>;
	pinctrl-10 = <&camera_pins_cam0_mclk_2ma>;
	pinctrl-11 = <&camera_pins_cam0_mclk_4ma>;
	pinctrl-12 = <&camera_pins_cam0_mclk_6ma>;
	pinctrl-13 = <&camera_pins_cam0_mclk_8ma>;
	pinctrl-14 = <&camera_pins_cam1_mclk_off>;
	pinctrl-15 = <&camera_pins_cam1_mclk_2ma>;
	pinctrl-16 = <&camera_pins_cam1_mclk_4ma>;
	pinctrl-17 = <&camera_pins_cam1_mclk_6ma>;
	pinctrl-18 = <&camera_pins_cam1_mclk_8ma>;
	pinctrl-19 = <&camera_pins_cam2_mclk_off>;
	pinctrl-20 = <&camera_pins_cam2_mclk_2ma>;
	pinctrl-21 = <&camera_pins_cam2_mclk_4ma>;
	pinctrl-22 = <&camera_pins_cam2_mclk_6ma>;
	pinctrl-23 = <&camera_pins_cam2_mclk_8ma>;
	pinctrl-24 = <&camera_pins_cam4_mclk_off>;
	pinctrl-25 = <&camera_pins_cam4_mclk_2ma>;
	pinctrl-26 = <&camera_pins_cam4_mclk_4ma>;
	pinctrl-27 = <&camera_pins_cam4_mclk_6ma>;
	pinctrl-28 = <&camera_pins_cam4_mclk_8ma>;
	pinctrl-29 = <&cam0_ldo_plugic_en_0>;
	pinctrl-30 = <&cam0_ldo_plugic_en_1>;
	pinctrl-31 = <&cam1_ldo_plugic_en_0>;
	pinctrl-32 = <&cam1_ldo_plugic_en_1>;
	pinctrl-33 = <&cam2_ldo_plugic_en_0>;
	pinctrl-34 = <&cam2_ldo_plugic_en_1>;
	pinctrl-35 = <&cam4_ldo_plugic_en_0>;
	pinctrl-36 = <&cam4_ldo_plugic_en_1>;
	status = "okay";
};
/* CAMERA GPIO end */

/* yangtao add for tf start */
&msdc1 {
	fast_power_off;
#ifndef CONFIG_FPGA_EARLY_PORTING
	pinctl = <&msdc1_pins_default>;
	pinctl_sdr104 = <&msdc1_pins_sdr104>;
	pinctl_sdr50 = <&msdc1_pins_sdr50>;
	pinctl_ddr50 = <&msdc1_pins_ddr50>;
	pinctl_hs200 = <&msdc1_pins_hs200>;
#endif
};

#ifndef CONFIG_FPGA_EARLY_PORTING
&pio {
	msdc1_pins_default: msdc1@default {
		pins_cmd {
			drive-strength = /bits/ 8 <2>;
		};
		pins_dat {
			drive-strength = /bits/ 8 <2>;
		};
		pins_clk {
			drive-strength = /bits/ 8 <5>;
		};
	};

	msdc1_pins_sdr104: msdc1@sdr104 {
		pins_cmd {
			drive-strength = /bits/ 8 <2>;
		};
		pins_dat {
			drive-strength = /bits/ 8 <2>;
		};
		pins_clk {
			drive-strength = /bits/ 8 <5>;
		};
	};

	msdc1_pins_sdr50: msdc1@sdr50 {
		pins_cmd {
			drive-strength = /bits/ 8 <2>;
		};
		pins_dat {
			drive-strength = /bits/ 8 <2>;
		};
		pins_clk {
			drive-strength = /bits/ 8 <5>;
		};
	};

	msdc1_pins_ddr50: msdc1@ddr50 {
		pins_cmd {
			drive-strength = /bits/ 8 <2>;
		};
		pins_dat {
			drive-strength = /bits/ 8 <2>;
		};
		pins_clk {
			drive-strength = /bits/ 8 <5>;
		};
	};

	msdc1_pins_hs200: msdc1@hs200 {
		pins_cmd {
			drive-strength = /bits/ 8 <2>;
		};
		pins_dat {
			drive-strength = /bits/ 8 <2>;
		};
		pins_clk {
			drive-strength = /bits/ 8 <5>;
		};
	};
};
#endif

&mt6360_ldo {
	sdcard_det_en = <1>;
	sdcard_hlact = <0>;
};
/* yangtao add for tf end */

/*#include "mediatek/cust_mt6833_camera.dtsi"*/
#include "mediatek/cust_vivo_PD2159F_EX.dtsi"
#include "mediatek/vivo_tp_setting/mtk-vivo-tp-PD2159F_EX.dtsi"
#include "mediatek/fingerprint/mt6833-vivo-fp-PD2159F_EX.dtsi"

/* add by sensor team for SAR Power */
&pio {
	sar_power_state: sar_power_rf_detect {
		pins_cmd0_dat {
			pinmux = <PINMUX_GPIO22__FUNC_GPIO22>,<PINMUX_GPIO19__FUNC_GPIO19>,<PINMUX_GPIO21__FUNC_GPIO21>;
			slew-rate = <0>;
			bias-disable;
		};
	};
};

&sar_power {
	status="okay";
	pinctrl-names = "default";
	pinctrl-0 = <&sar_power_state>;
	sar-power-rf-detect,gpios= <&pio 22 0x0>;
	sar-power-rf-detect_1,gpios= <&pio 19 0x0>;
	sar-power-rf-detect_2,gpios= <&pio 21 0x0>;
};
/* add by sensor team for SAR Power */
/*End of this file, DO NOT ADD ANYTHING HERE*/
